# N572F072_v3 register map
File version: 1.0
Registers are 32-bit, read-write, reset 0x0 unless marked. A register's access mark holds for its fields unless they carry their own. Offsets are from the block's base; [hi:lo] are bit positions; {n}, {i} and the like mark numbered series.

## APU — APU Register Map
Base 0x50008000
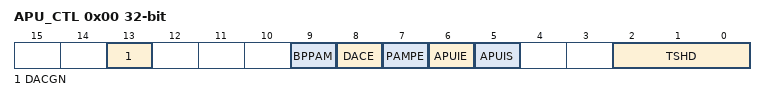
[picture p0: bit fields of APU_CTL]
0x00 APU_CTL — APU Control Register
  [13] DACGN — DAC Output Current Control. This bit is effective only when BPPAM is "1".
    0=3mA; 1=5mA
  [9] BPPAM — Bypass Power Amplifier, DAC Output To Pin
    0=SPK+/DAC pin is one of power amplifier output,; 1=SPK+/DAC pin is current DAC output, no output on SPK-
  [8] DACE — DAC Enable
    0=Disable DAC function; 1=Enable DAC function
  [7] PAMPE — Power Amplifier Enable
    0=Disable PA function; 1=Enable PA function
  [6] APUIE — APU Interrupt Enable
    0=Disable the APU threshold interrupt; 1=Enable the APU threshold interrupt
  [5] APUIS — APU Interrupt Status. This flag is set by hardware when APU threshold is met. Software can clear this bit by writing a zero to it.
    0=APU threshold interrupt does not occur; 1=APU threshold interrupt occur
  [2:0] TSHD — APU Interrupt Threshold
    {v}=Buffer {v} is read out by APU (v=0..7)
0x04 APU_VM — APU Volume Control Register
  [2:0] VOLUM — APU Volume Adjustment
    0=0 dB; 1=-3 dB; 2=-6 dB; 3=-9 dB; 4=-12 dB; 5=-15 dB; 6=-18 dB
0x0C APU_CH1DAT0 — APU channel 1 Data Buffer Register
  [15:0] PCM — PCM Data Of Channel 1. This field contains 16-bit PCM data that are one of the Mixer input. User needs to take care of the effective bit of PCM because the H/W mixer output is clipped to 13 bits automatically. The data format of PCM is 2'complement.
{0x10+4i} APU_CH0DAT{i} (i=0..7) — APU channel 0 Data Buffer Register 0
  [15:0] PCM — PCM Data Of Channel 0. This field contains 16-bit PCM data that will be sent to Mixer APU H/W. User needs to take care of the effective bit of PCM because the H/W Mixer output is clipped to 13 bits automatically. The data format of PCM is 2'complement.

## CFG — CONFIGURE Register Map
Base 0x00300000
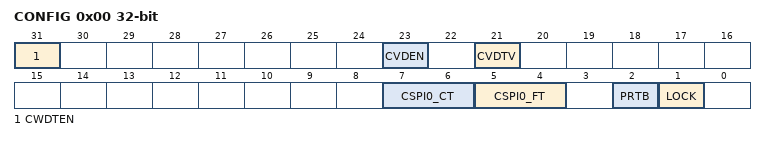
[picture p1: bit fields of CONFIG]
0x00 CONFIG — User Configuration Memory
  [31] CWDTEN — Watchdog Enable
    0=Watchdog is disabled after power on; 1=Watchdog is enabled after power on
  [23] CVDEN — Voltage Detector Enable
    0=Enable Voltage Detector after power on; 1=Disable Voltage Detector after power on
  [21] CVDTV — Voltage Detector Threshold Voltage Selection
  [7:6] CSPI0_CT — Coarse Timing Control for SPI0 Data Receiving After Power On. These bits are used to adjust receiving clock for latching serial-in data correctly in high speed transmission mode.
    0=Receiving data clock is same as the SPI0_CLK; 1=Receiving data clock is delayed 2 half SPI0_CLK clock cycle,; 2=Receiving data clock is delayed 3 half SPI0_CLK clock cycle,; 3=Receiving data clock is delayed 1 half SPI0_CLK clock cycle ,
  [5:4] CSPI0_FT — Fine Timing Control for SPI0 Data Receiving After Power On. The delay timing selected by CSPI0_CT can be further tuned finely by CSPI0_FT. Note: The extra delay is implemented by delay chains. The accuracy of delay time would base on process deviation.
    0=Receiving data clock has extra 7.5nS delay; 1=Receiving data clock has extra 5.0nS delay,; 2=Receiving data clock has extra 2.5nS delay,; 3=Receiving data clock has no extra delay,
  [2] PRTB — Protection On 8K Bytes Flash. This bit is effective only for the part of 72KB flash.
    0=ISP function only can operate on the 64KB Flash (address: 0x0000~0xFFFF) and CONFIG, and cannot operate on the 8KB Flash (address: 0x10000~0x11FFF); 1=ISP function can operate on the whole 72KB Flash (address: 0x00000~0x11FFF) and CONFIG
  [1] LOCK — Security Lock. When flash data is locked,(1) only device ID, CONFIG can be read by Writer and ICP thru serial debug interface. Other data are locked as 0xFFFFFFFF.(2) ISP can read data in legal address regardless of LOCK bit value. (3) SWD interface cannot access internal RAM and Flash
    0=Flash data are locked; 1=Flash data are not locked

## FMC — FMC Register Map
Base 0x5000C000
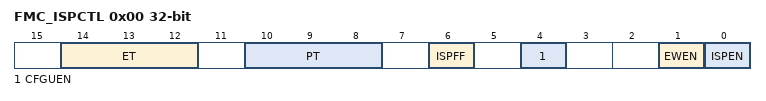
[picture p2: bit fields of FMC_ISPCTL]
0x00 FMC_ISPCTL — ISP Control Register
  [14:12] ET — Flash Page Erase Time
    0=2.0 ms (default); 1=2.5 ms; 2=3.0 ms; 3=1.5 ms; 4=1.0 ms; 5=0.75 ms; 6=4.0 ms; 7=5.0 ms
  [10:8] PT — Flash Program Time
    0=20 (s (default); 1=25 (s; 2=30 (s; 3=35 (s; 4=40 (s; 5=45 (s; 6=10 (s; 7=15 (s
  [6] ISPFF — ISP Fail Flag. This bit is set by hardware when a triggered ISP meets any of the following conditions: MCU writes (or erase) to Flash when EWEN is "0". Destination address is illegal, such as over an available range. Destination address is within 0x10000~0x11FFF if PRTB bit of CONFIG is "0". Destination address is within 0x00000~0x0FFFF if MOTPB bit of MAP0 is "0". Destination address is within 0x10000~0x11FFF if both MOTPB and SOTPB bits of MAP0 are "0". . Write 1 to clear.
  [4] CFGUEN — CONFIG Update Enable. When enabled, ISP functions can access the CONFIG address space and modify device configuration area.
    0=Disable; 1=Enable
  [1] EWEN — Enable Erase/Write Of ISP Function
    0=Disable erase/write; 1=Enable erase/write
  [0] ISPEN — ISP Enable
    0=Disable ISP function; 1=Enable ISP function
0x04 FMC_ISPADDR — ISP Address Register
  [31:0] ISPADDR — ISP Address Register. This is the memory address register that a subsequent ISP command will access. ISP operation are carried out on 32bit words only, consequently ISPADDR [1:0] must be 00b for correct ISP operation. N572F072/P072 equips with an 18Kx32 bits embedded flash.
0x08 FMC_ISPDAT — ISP Data Register
  [31:0] ISPDAT — ISP Data Register. Write data to this register before an ISP program operation. Read data from this register after an ISP read operation
0x0C FMC_ISPCMD — ISP Command Register
  [5:0] CMD — ISP Command. Operation Mode : CMD -------------------- ------- Standby : 0x3X. Read CID : 0x0B. Read DID : 0x0C. Flash Page Erase : 0x22. Flash Program : 0x21. Flash Read : 0x00
0x10 FMC_ISPTRG — ISP Trigger Control Register
  [0] ISPGO — ISP Start Trigger. Write 1 to start ISP operation. This bit will be cleared to 0 by hardware automatically when ISP operation is finished.
    0=ISP operation is finished; 1=ISP is on going
